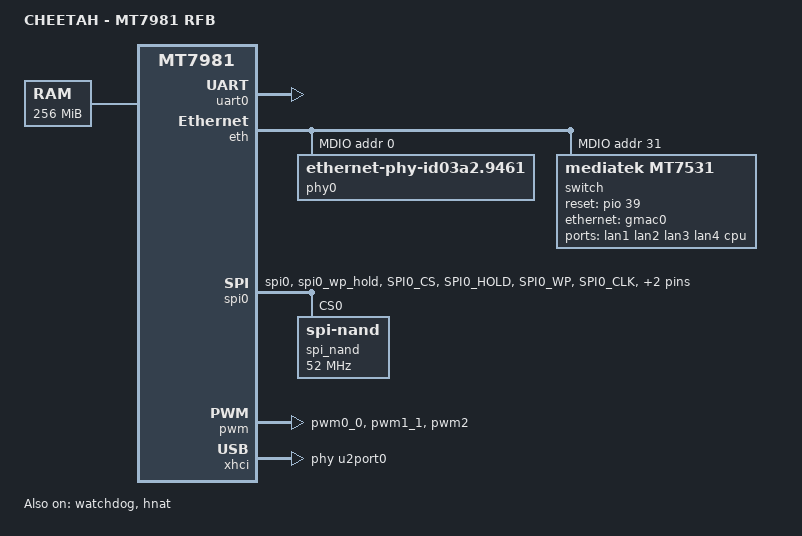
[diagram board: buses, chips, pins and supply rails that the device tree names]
/dts-v1/;
#include "mt7981.dtsi"
/ {
	model = "CHEETAH - MT7981 RFB";
	compatible = "mediatek,mt7981-spim-snand-rfb";
	chosen {
		bootargs = "console=ttyS0,115200n1 loglevel=8  \
				earlycon=uart8250,mmio32,0x11002000";
	};

	memory {
		// fpga ddr2: 128MB*2
		reg = <0 0x40000000 0 0x10000000>;
	};

	aliases {
		ethernet0 = "/ethernet@15100000/mac@0";
		ethernet1 = "/ethernet@15100000/mac@1";
	};
};

&uart0 {
	status = "okay";
};

&watchdog {
	status = "okay";
};

&eth {
        status = "okay";

        gmac0: mac@0 {
                compatible = "mediatek,eth-mac";
                reg = <0>;
                phy-mode = "2500base-x";
		local-mac-address = [000000000000];

                fixed-link {
                        speed = <2500>;
                        full-duplex;
                        pause;
                };
        };

	gmac1: mac@1 {
		compatible = "mediatek,eth-mac";
		reg = <1>;
		phy-mode = "gmii";
		phy-handle = <&phy0>;
	};

        mdio: mdio-bus {
                #address-cells = <1>;
                #size-cells = <0>;

		phy0: ethernet-phy@0 {
			compatible = "ethernet-phy-id03a2.9461";
			reg = <0>;
			phy-mode = "gmii";
			nvmem-cells = <&phy_calibration>;
			nvmem-cell-names = "phy-cal-data";
		};

		switch@0 {
                        compatible = "mediatek,mt7531";
                        reg = <31>;
                        reset-gpios = <&pio 39 0>;

                        ports {
                                #address-cells = <1>;
                                #size-cells = <0>;

                                port@0 {
                                        reg = <0>;
                                        label = "lan1";
                                };

                                port@1 {
                                        reg = <1>;
                                        label = "lan2";
                                };

                                port@2 {
                                        reg = <2>;
                                        label = "lan3";
                                };

                                port@3 {
                                        reg = <3>;
                                        label = "lan4";
                                };

                                port@6 {
                                        reg = <6>;
                                        label = "cpu";
                                        ethernet = <&gmac0>;
                                        phy-mode = "2500base-x";

                                        fixed-link {
                                                speed = <2500>;
                                                full-duplex;
                                                pause;
                                        };
                                };
                        };
                };
        };
};

&hnat {
	mtketh-wan = "eth1";
	mtketh-lan = "lan";
	mtketh-max-gmac = <2>;
	status = "okay";
};

&spi0 {
	pinctrl-names = "default";
	pinctrl-0 = <&spi0_flash_pins>;
	status = "okay";
	spi_nand: spi_nand@0 {
		#address-cells = <1>;
		#size-cells = <1>;
		compatible = "spi-nand";
		reg = <0>;
		spi-max-frequency = <52000000>;
		spi-tx-buswidth = <4>;
		spi-rx-buswidth = <4>;
	};
};

&spi1 {
	pinctrl-names = "default";
	pinctrl-0 = <&spic_pins>;
	status = "disabled";
};

&pio {

	i2c_pins: i2c-pins-g0 {
                mux {
                        function = "i2c";
                        groups = "i2c0_0";
                };
        };

        pcm_pins: pcm-pins-g0 {
                mux {
                        function = "pcm";
                        groups = "pcm";
                };
        };

        pwm0_pin: pwm0-pin-g0 {
                mux {
                        function = "pwm";
                        groups = "pwm0_0";
                };
        };

        pwm1_pin: pwm1-pin-g1 {
                mux {
                        function = "pwm";
                        groups = "pwm1_1";
                };
        };

        pwm2_pin: pwm2-pin {
                mux {
                        function = "pwm";
                        groups = "pwm2";
                };
        };

	spi0_flash_pins: spi0-pins {
		mux {
			function = "spi";
			groups = "spi0", "spi0_wp_hold";
		};

		conf-pu {
			pins = "SPI0_CS", "SPI0_HOLD", "SPI0_WP";
			drive-strength = <MTK_DRIVE_8mA>;
			bias-pull-up = <MTK_PUPD_SET_R1R0_11>;
		};

		conf-pd {
			pins = "SPI0_CLK", "SPI0_MOSI", "SPI0_MISO";
			drive-strength = <MTK_DRIVE_8mA>;
			bias-pull-down = <MTK_PUPD_SET_R1R0_11>;
		};
	};

	spic_pins: spi1-pins {
		mux {
			function = "spi";
			groups = "spi1_1";
		};
	};

	uart1_pins: uart1-pins-g1 {
                mux {
                        function = "uart";
                        groups = "uart1_1";
                };
        };

	uart2_pins: uart2-pins-g1 {
		mux {
                        function = "uart";
                        groups = "uart2_1";
                };
        };
};

&pwm {
	pinctrl-names = "default";
	pinctrl-0 = <&pwm0_pin &pwm1_pin &pwm2_pin>;
	interrupts = <GIC_SPI 137 IRQ_TYPE_LEVEL_HIGH>;
	status = "okay";
};

&xhci {
	mediatek,u3p-dis-msk = <0x0>;
	phys = <&u2port0 PHY_TYPE_USB2>,
	       <&u3port0 PHY_TYPE_USB3>;
	status = "okay";
};
